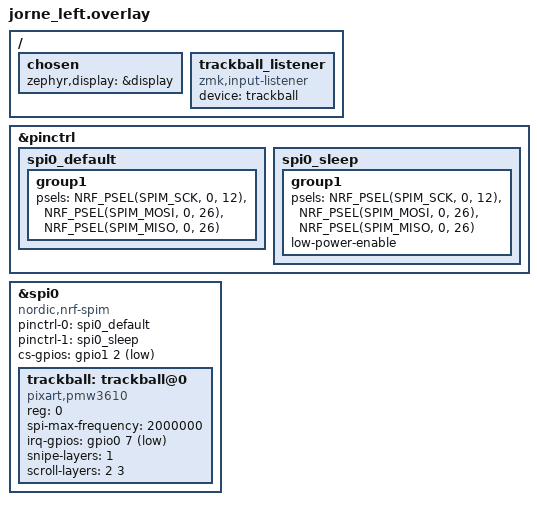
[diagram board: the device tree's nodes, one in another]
#include <dt-bindings/zmk/ext_power.h>

/ {
    
    chosen {
        zephyr,display = &display;
    };
};

//ref https://grok.com/c/0f015a08-e56b-4161-a035-fd4ae34c6a79?rid=a247c598-bc4f-4b68-99a6-8e43b76befae
/* Define pin control groups for your custom SPI pins */
&pinctrl {
    spi0_default: spi0_default {
        group1 {
            psels = <NRF_PSEL(SPIM_SCK,  0, 12)>,   /* SCLK = P0.12 */
                    <NRF_PSEL(SPIM_MOSI, 0, 26)>;   /* MOSI = P0.26 */
                    /* MISO is not required physically for nice!view */
        };
    };

    spi0_sleep: spi0_sleep {
        group1 {
            psels = <NRF_PSEL(SPIM_SCK,  0, 12)>,
                    <NRF_PSEL(SPIM_MOSI, 0, 26)>;
            low-power-enable;
        };
    };
};

/* This is the critical part: define the exact label the nice_view shield expects */
&spi0 {  /* Use &spi1 (or &spi0 if it's free on left half) */
    status = "okay";
    compatible = "nordic,nrf-spim";
    pinctrl-0 = <&spi0_default>;
    pinctrl-1 = <&spi0_sleep>;
    pinctrl-names = "default", "sleep";

    /* nice!view uses ACTIVE_HIGH CS polarity */
    cs-gpios = <&gpio1 4 GPIO_ACTIVE_HIGH>;  /* CS = P1.04 */
};

/* Optional: Enable display features and tune power */
//CONFIG_ZMK_DISPLAY=y
//CONFIG_ZMK_DISPLAY_STATUS_SCREEN_CUSTOM=n  /* Use built-in if preferred; default nice!view widget is vertical */
//refer https://grok.com/c/0f015a08-e56b-4161-a035-fd4ae34c6a79?rid=67fb8178-267c-42bf-a910-2bfbacafe1a1

&pinctrl {
    spi0_default: spi0_default {
        group1 {
            psels = <NRF_PSEL(SPIM_SCK,  0, 12)>,
                    <NRF_PSEL(SPIM_MOSI, 0, 26)>,
                    <NRF_PSEL(SPIM_MISO, 0, 26)>;  /* same pin as MOSI */
        };
    };

    /* sleep group similarly */
    spi0_sleep: spi0_sleep {
        group1 {
            psels = <NRF_PSEL(SPIM_SCK,  0, 12)>,
                    <NRF_PSEL(SPIM_MOSI, 0, 26)>,
                    <NRF_PSEL(SPIM_MISO, 0, 26)>;
            low-power-enable;
        };
    };
};

&spi0 {
    status = "okay";
    compatible = "nordic,nrf-spim";
    pinctrl-0 = <&spi0_default>;
    pinctrl-1 = <&spi0_sleep>;
    pinctrl-names = "default", "sleep";
    cs-gpios = <&gpio1 2 GPIO_ACTIVE_LOW>;

    trackball: trackball@0 {
        status = "okay";
        compatible = "pixart,pmw3610";
        reg = <0>;
        spi-max-frequency = <2000000>;
        irq-gpios = <&gpio0 7 (GPIO_ACTIVE_LOW | GPIO_PULL_UP)>; //MOT pin

        /* Optional useful properties — adjust as needed */
        snipe-layers = <1>;           /* example: precision mode on layer 1 */
        scroll-layers = <2 3>;        /* scroll mode on layers 2 & 3 */
        /* automouse-layer = <4>; */  /* auto-switch to mouse layer — many prefer keymap listener instead */
    };
};

/ {
    trackball_listener {
        compatible = "zmk,input-listener";
        device = <&trackball>;
    };
};
